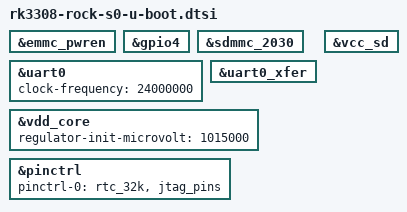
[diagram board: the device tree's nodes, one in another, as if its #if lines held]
// SPDX-License-Identifier: GPL-2.0+

#include "rk3308-u-boot.dtsi"

&emmc_pwren {
	bootph-pre-ram;
	bootph-some-ram;
};

&gpio4 {
	bootph-pre-ram;
};

&sdmmc_2030 {
	bootph-pre-ram;
};

&uart0 {
	bootph-all;
	clock-frequency = <24000000>;
};

&uart0_xfer {
	bootph-all;
};

&vcc_sd {
	bootph-pre-ram;
};

&vdd_core {
	regulator-init-microvolt = <1015000>;
};

#ifdef CONFIG_ROCKCHIP_RK3308_DEBUG_JTAG
/* Keep SWD on GPIO1_C6/C7 usable while U-Boot runs */
&pinctrl {
	pinctrl-names = "default";
	/* keep the board hog (rtc_32k) from rk3308-rock-s0.dts */
	pinctrl-0 = <&rtc_32k &jtag_pins>;
};
#endif
